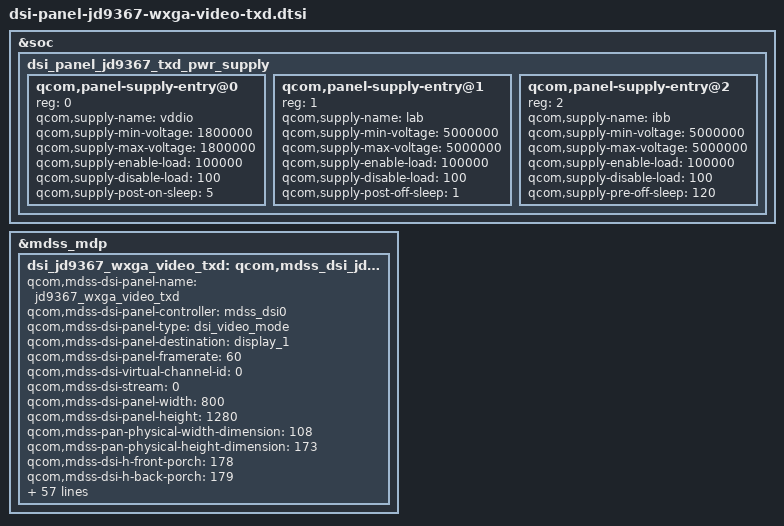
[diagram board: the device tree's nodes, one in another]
/* Copyright (c) 2013, The Linux Foundation. All rights reserved.
 *
 * This program is free software; you can redistribute it and/or modify
 * it under the terms of the GNU General Public License version 2 and
 * only version 2 as published by the Free Software Foundation.
 *
 * This program is distributed in the hope that it will be useful,
 * but WITHOUT ANY WARRANTY; without even the implied warranty of
 * MERCHANTABILITY or FITNESS FOR A PARTICULAR PURPOSE.  See the
 * GNU General Public License for more details.
 */

/*---------------------------------------------------------------------------
 * This file is autogenerated file using gcdb parser. Please do not edit it.
 * Update input XML file to add a new entry or update variable in this file
 * VERSION = "1.0"
 *---------------------------------------------------------------------------*/
&soc {
	dsi_panel_jd9367_txd_pwr_supply: dsi_panel_jd9367_txd_pwr_supply {
		#address-cells = <1>;
		#size-cells = <0>;

		qcom,panel-supply-entry@0 {
			reg = <0>;
			qcom,supply-name = "vddio";
			qcom,supply-min-voltage = <1800000>;
			qcom,supply-max-voltage = <1800000>;
			qcom,supply-enable-load = <100000>;
			qcom,supply-disable-load = <100>;
			qcom,supply-post-on-sleep = <5>;
		};

		qcom,panel-supply-entry@1 {
			reg = <1>;
			qcom,supply-name = "lab";
			qcom,supply-min-voltage = <5000000>;
			qcom,supply-max-voltage = <5000000>;
			qcom,supply-enable-load = <100000>;
			qcom,supply-disable-load = <100>;
			qcom,supply-post-off-sleep = <1>;
		};

		qcom,panel-supply-entry@2 {
			reg = <2>;
			qcom,supply-name = "ibb";
			qcom,supply-min-voltage = <5000000>;
			qcom,supply-max-voltage = <5000000>;
			qcom,supply-enable-load = <100000>;
			qcom,supply-disable-load = <100>;
			qcom,supply-pre-off-sleep = <120>;
		};
	};
};
&mdss_mdp {
	dsi_jd9367_wxga_video_txd: qcom,mdss_dsi_jd9367_wxga_video_txd {
		qcom,mdss-dsi-panel-name = "jd9367_wxga_video_txd";
		qcom,mdss-dsi-panel-controller = <&mdss_dsi0>;
		qcom,mdss-dsi-panel-type = "dsi_video_mode";
		qcom,mdss-dsi-panel-destination = "display_1";
		qcom,mdss-dsi-panel-framerate = <60>;
		qcom,mdss-dsi-virtual-channel-id = <0>;
		qcom,mdss-dsi-stream = <0>;
		qcom,mdss-dsi-panel-width = <800>;
		qcom,mdss-dsi-panel-height = <1280>;
		qcom,mdss-pan-physical-width-dimension = <108>;
		qcom,mdss-pan-physical-height-dimension = <173>;
		qcom,mdss-dsi-h-front-porch = <178>;
		qcom,mdss-dsi-h-back-porch = <179>;
		qcom,mdss-dsi-h-pulse-width = <20>;
		qcom,mdss-dsi-h-sync-skew = <0>;
		qcom,mdss-dsi-v-back-porch = <10>;
		qcom,mdss-dsi-v-front-porch = <30>;
		qcom,mdss-dsi-v-pulse-width = <4>;
		qcom,mdss-dsi-h-left-border = <0>;
		qcom,mdss-dsi-h-right-border = <0>;
		qcom,mdss-dsi-v-top-border = <0>;
		qcom,mdss-dsi-v-bottom-border = <0>;
		qcom,mdss-dsi-bpp = <24>;
		qcom,mdss-dsi-color-order = "rgb_swap_rgb";
		qcom,mdss-dsi-underflow-color = <0xff>;
		qcom,mdss-dsi-border-color = <0>;
		qcom,mdss-dsi-on-command = [39 01 00 00 00 00 02 E0 00
					39 01 00 00 00 00 02 E1 93
					39 01 00 00 00 00 02 E2 65
					39 01 00 00 00 00 02 E3 F8
					39 01 00 00 00 00 02 80 03
					39 01 00 00 00 00 02 E0 01
					39 01 00 00 00 00 02 00 00
					39 01 00 00 00 00 02 01 6E
					39 01 00 00 00 00 02 03 00
					39 01 00 00 00 00 02 04 75
					39 01 00 00 00 00 02 17 00
					39 01 00 00 00 00 02 18 D7
					39 01 00 00 00 00 02 19 01
					39 01 00 00 00 00 02 1A 00
					39 01 00 00 00 00 02 1B D7
					39 01 00 00 00 00 02 1C 01
					39 01 00 00 00 00 02 1F 79
					39 01 00 00 00 00 02 20 2D
					39 01 00 00 00 00 02 21 2D
					39 01 00 00 00 00 02 22 0F
					39 01 00 00 00 00 02 35 2A
					39 01 00 00 00 00 02 37 09
					39 01 00 00 00 00 02 38 04
					39 01 00 00 00 00 02 39 02
					39 01 00 00 00 00 02 3A 04
					39 01 00 00 00 00 02 3C 70
					39 01 00 00 00 00 02 3D FF
					39 01 00 00 00 00 02 3E FF
					39 01 00 00 00 00 02 3F 7F
					39 01 00 00 00 00 02 40 06
					39 01 00 00 00 00 02 41 A0
					39 01 00 00 00 00 02 43 1E
					39 01 00 00 00 00 02 44 0D
					39 01 00 00 00 00 02 45 28
					39 01 00 00 00 00 02 4B 04
					39 01 00 00 00 00 02 55 0F
					39 01 00 00 00 00 02 56 01
					39 01 00 00 00 00 02 57 A9
					39 01 00 00 00 00 02 58 0A
					39 01 00 00 00 00 02 59 2A
					39 01 00 00 00 00 02 5A 37
					39 01 00 00 00 00 02 5B 19
					39 01 00 00 00 00 02 5D 78
					39 01 00 00 00 00 02 5E 57
					39 01 00 00 00 00 02 5F 45
					39 01 00 00 00 00 02 60 37
					39 01 00 00 00 00 02 61 33
					39 01 00 00 00 00 02 62 23
					39 01 00 00 00 00 02 63 27
					39 01 00 00 00 00 02 64 11
					39 01 00 00 00 00 02 65 29
					39 01 00 00 00 00 02 66 28
					39 01 00 00 00 00 02 67 27
					39 01 00 00 00 00 02 68 45
					39 01 00 00 00 00 02 69 32
					39 01 00 00 00 00 02 6A 40
					39 01 00 00 00 00 02 6B 39
					39 01 00 00 00 00 02 6C 2C
					39 01 00 00 00 00 02 6D 22
					39 01 00 00 00 00 02 6E 0E
					39 01 00 00 00 00 02 6F 02
					39 01 00 00 00 00 02 70 78
					39 01 00 00 00 00 02 71 57
					39 01 00 00 00 00 02 72 45
					39 01 00 00 00 00 02 73 37
					39 01 00 00 00 00 02 74 33
					39 01 00 00 00 00 02 75 23
					39 01 00 00 00 00 02 76 27
					39 01 00 00 00 00 02 77 11
					39 01 00 00 00 00 02 78 29
					39 01 00 00 00 00 02 79 28
					39 01 00 00 00 00 02 7A 27
					39 01 00 00 00 00 02 7B 45
					39 01 00 00 00 00 02 7C 32
					39 01 00 00 00 00 02 7D 40
					39 01 00 00 00 00 02 7E 39
					39 01 00 00 00 00 02 7F 2C
					39 01 00 00 00 00 02 80 22
					39 01 00 00 00 00 02 81 0E
					39 01 00 00 00 00 02 82 02
					39 01 00 00 00 00 02 E0 02
					39 01 00 00 00 00 02 00 40
					39 01 00 00 00 00 02 01 44
					39 01 00 00 00 00 02 02 46
					39 01 00 00 00 00 02 03 48
					39 01 00 00 00 00 02 04 4A
					39 01 00 00 00 00 02 05 4C
					39 01 00 00 00 00 02 06 4E
					39 01 00 00 00 00 02 07 57
					39 01 00 00 00 00 02 08 77
					39 01 00 00 00 00 02 09 55
					39 01 00 00 00 00 02 0A 50
					39 01 00 00 00 00 02 0B 55
					39 01 00 00 00 00 02 0C 55
					39 01 00 00 00 00 02 0D 55
					39 01 00 00 00 00 02 0E 55
					39 01 00 00 00 00 02 0F 55
					39 01 00 00 00 00 02 10 55
					39 01 00 00 00 00 02 11 55
					39 01 00 00 00 00 02 12 55
					39 01 00 00 00 00 02 13 52
					39 01 00 00 00 00 02 14 55
					39 01 00 00 00 00 02 15 55
					39 01 00 00 00 00 02 16 41
					39 01 00 00 00 00 02 17 45
					39 01 00 00 00 00 02 18 47
					39 01 00 00 00 00 02 19 49
					39 01 00 00 00 00 02 1A 4B
					39 01 00 00 00 00 02 1B 4D
					39 01 00 00 00 00 02 1C 4F
					39 01 00 00 00 00 02 1D 57
					39 01 00 00 00 00 02 1E 77
					39 01 00 00 00 00 02 1F 55
					39 01 00 00 00 00 02 20 51
					39 01 00 00 00 00 02 21 55
					39 01 00 00 00 00 02 22 55
					39 01 00 00 00 00 02 23 55
					39 01 00 00 00 00 02 24 55
					39 01 00 00 00 00 02 25 55
					39 01 00 00 00 00 02 26 55
					39 01 00 00 00 00 02 27 55
					39 01 00 00 00 00 02 28 55
					39 01 00 00 00 00 02 29 53
					39 01 00 00 00 00 02 2A 55
					39 01 00 00 00 00 02 2B 55
					39 01 00 00 00 00 02 2C 11
					39 01 00 00 00 00 02 2D 0F
					39 01 00 00 00 00 02 2E 0D
					39 01 00 00 00 00 02 2F 0B
					39 01 00 00 00 00 02 30 09
					39 01 00 00 00 00 02 31 07
					39 01 00 00 00 00 02 32 05
					39 01 00 00 00 00 02 33 17
					39 01 00 00 00 00 02 34 17
					39 01 00 00 00 00 02 35 15
					39 01 00 00 00 00 02 36 01
					39 01 00 00 00 00 02 37 15
					39 01 00 00 00 00 02 38 15
					39 01 00 00 00 00 02 39 15
					39 01 00 00 00 00 02 3A 15
					39 01 00 00 00 00 02 3B 15
					39 01 00 00 00 00 02 3C 15
					39 01 00 00 00 00 02 3D 15
					39 01 00 00 00 00 02 3E 15
					39 01 00 00 00 00 02 3F 13
					39 01 00 00 00 00 02 40 15
					39 01 00 00 00 00 02 41 15
					39 01 00 00 00 00 02 42 10
					39 01 00 00 00 00 02 43 0E
					39 01 00 00 00 00 02 44 0C
					39 01 00 00 00 00 02 45 0A
					39 01 00 00 00 00 02 46 08
					39 01 00 00 00 00 02 47 06
					39 01 00 00 00 00 02 48 04
					39 01 00 00 00 00 02 49 17
					39 01 00 00 00 00 02 4A 17
					39 01 00 00 00 00 02 4B 15
					39 01 00 00 00 00 02 4C 00
					39 01 00 00 00 00 02 4D 15
					39 01 00 00 00 00 02 4E 15
					39 01 00 00 00 00 02 4F 15
					39 01 00 00 00 00 02 50 15
					39 01 00 00 00 00 02 51 15
					39 01 00 00 00 00 02 52 15
					39 01 00 00 00 00 02 53 15
					39 01 00 00 00 00 02 54 15
					39 01 00 00 00 00 02 55 12
					39 01 00 00 00 00 02 56 15
					39 01 00 00 00 00 02 57 15
					39 01 00 00 00 00 02 58 40
					39 01 00 00 00 00 02 59 00
					39 01 00 00 00 00 02 5A 00
					39 01 00 00 00 00 02 5B 10
					39 01 00 00 00 00 02 5C 06
					39 01 00 00 00 00 02 5D 40
					39 01 00 00 00 00 02 5E 00
					39 01 00 00 00 00 02 5F 00
					39 01 00 00 00 00 02 60 40
					39 01 00 00 00 00 02 61 03
					39 01 00 00 00 00 02 62 04
					39 01 00 00 00 00 02 63 60
					39 01 00 00 00 00 02 64 60
					39 01 00 00 00 00 02 65 75
					39 01 00 00 00 00 02 66 0C
					39 01 00 00 00 00 02 67 B4
					39 01 00 00 00 00 02 68 04
					39 01 00 00 00 00 02 69 64
					39 01 00 00 00 00 02 6A 60
					39 01 00 00 00 00 02 6B 10
					39 01 00 00 00 00 02 6C 00
					39 01 00 00 00 00 02 6D 02
					39 01 00 00 00 00 02 6E 04
					39 01 00 00 00 00 02 6F C8
					39 01 00 00 00 00 02 70 00
					39 01 00 00 00 00 02 71 00
					39 01 00 00 00 00 02 72 06
					39 01 00 00 00 00 02 73 7B
					39 01 00 00 00 00 02 74 00
					39 01 00 00 00 00 02 75 BC
					39 01 00 00 00 00 02 76 00
					39 01 00 00 00 00 02 77 0D
					39 01 00 00 00 00 02 78 2C
					39 01 00 00 00 00 02 79 00
					39 01 00 00 00 00 02 7A 00
					39 01 00 00 00 00 02 7B 00
					39 01 00 00 00 00 02 7C 00
					39 01 00 00 00 00 02 7D 03
					39 01 00 00 00 00 02 7E 7B
					39 01 00 00 00 00 02 E0 03
					39 01 00 00 00 00 02 9B 04
					39 01 00 00 00 00 02 AF 20
					39 01 00 00 00 00 02 E0 04
					39 01 00 00 00 00 02 09 11
					39 01 00 00 00 00 02 0E 48
					39 01 00 00 00 00 02 27 48
					39 01 00 00 00 00 02 2B 2B
					39 01 00 00 00 00 02 2E 44
					39 01 00 00 00 00 02 2D 03
					39 01 00 00 00 00 02 41 FF
					39 01 00 00 00 00 02 4B FF
					39 01 00 00 00 00 02 E0 05
					39 01 00 00 00 00 02 12 72
					39 01 00 00 00 00 02 E0 00
					39 01 00 00 00 00 02 E6 02
					39 01 00 00 00 00 02 E7 06
					05 01 00 00 78 00 02 11 00
					05 01 00 00 05 00 02 29 00
					39 01 00 00 00 00 02 35 00];
		qcom,mdss-dsi-off-command = [05 01 00 00 14 00 02 28 00
					05 01 00 00 78 00 02 10 00];
		qcom,mdss-dsi-on-command-state = "dsi_lp_mode";
		qcom,mdss-dsi-off-command-state = "dsi_lp_mode";
		qcom,mdss-dsi-h-sync-pulse = <1>;
		qcom,mdss-dsi-traffic-mode = "burst_mode";
		qcom,mdss-dsi-lane-map = "lane_map_0123";
		qcom,mdss-dsi-bllp-eof-power-mode;
		qcom,mdss-dsi-bllp-power-mode;
		qcom,mdss-dsi-lane-0-state;
		qcom,mdss-dsi-lane-1-state;
		qcom,mdss-dsi-lane-2-state;
		qcom,mdss-dsi-lane-3-state;
		qcom,mdss-dsi-panel-timings-phy-12nm = [0C 07 0B 03 00 06 03 09];
		//qcom,mdss-dsi-t-clk-post = <0x04>;
		//qcom,mdss-dsi-t-clk-pre = <0x1A>;
		qcom,mdss-dsi-dma-trigger = "trigger_sw";
		qcom,mdss-dsi-mdp-trigger = "none";
		qcom,mdss-dsi-bl-min-level = <1>;
		qcom,mdss-dsi-bl-max-level = <255>;
		qcom,mdss-dsi-bl-pmic-control-type = "bl_ctrl_pwm";
		qcom,mdss-dsi-bl-pmic-pwm-frequency = <50>;
		qcom,mdss-dsi-bl-pmic-bank-select = <0>;
		qcom,mdss-dsi-pwm-gpio = <&pm8953_gpios 8 0>;
		ss,blmap-size = <256>;
		ss,blmap = < 0 2 2 2 2 2 2 2 2 2
					2 2 3 3 4 5 6 7 8 9
					10 11 12 13 14 15 16 17 18 19
					20 21 22 23 24 25 26 27 28 29
					30 31 32 33 34 35 36 37 38 39
					40 41 42 43 44 45 46 47 48 49
					50 51 52 53 54 55 56 57 58 59
					60 61 62 63 64 65 66 67 68 69
					70 71 72 73 74 75 76 77 78 79
					80 81 82 83 84 85 86 87 88 89
					90 91 92 93 94 95 96 97 98 99
					100 101 102 103 104 105 106 107 108 109
					110 111 112 113 114 115 116 117 118 119
					120 121 122 123 124 125 126 127 128 129
					130 131 132 133 134 135 136 137 138 139
					140 141 142 143 144 145 146 147 148 149
					150 151 152 153 154 155 156 157 158 159
					160 161 162 163 164 165 166 167 168 169
					170 171 172 173 174 175 176 177 178 179
					180 181 182 183 184 185 186 187 188 189
					190 191 192 193 194 195 196 197 198 199
					200 201 202 203 204 205 206 207 208 209
					210 211 212 213 214 215 216 217 218 219
					220 221 222 223 224 225 226 227 228 229
					230 231 232 233 234 236 238 240 242 244
					246 248 250 252 254 255>;

		qcom,mdss-dsi-lp11-init;
		qcom,mdss-dsi-init-delay-us = <6000>;
		qcom,mdss-dsi-reset-sequence = <1 5>, <0 10>, <1 120>;
		qcom,esd-check-enabled;
		qcom,mdss-dsi-panel-status-command = [06 01 00 01 05 00 02 0A 08];
		qcom,mdss-dsi-panel-status-command-state = "dsi_lp_mode";
		qcom,mdss-dsi-panel-status-check-mode = "reg_read";
		qcom,mdss-dsi-panel-status-valid-params = <1>;
		qcom,mdss-dsi-panel-status-value = <0x9C>;
		qcom,mdss-dsi-panel-status-read-length = <3>;
		qcom,panel-supply-entries = <&dsi_panel_jd9367_txd_pwr_supply>;
	};
};
